# CY8C4245AXI_483 register map
File version: 0.1
PSoC 4200
Registers are 32-bit, read-write, no defined reset value unless marked. A register's access mark holds for its fields unless they carry their own. Offsets are from the block's base; lines under a group give offsets from that group; [hi:lo] are bit positions; {n}, {i} and the like mark numbered series; 'fields as' and 'values as' point back to an identical list; <NAME> marks a mode.

## Memory map
0x00000000 Timer_1
0x00000000 ADC — Sequencing SAR ADC
0x00000000 IDAC

## Timer_1
Base 0x00000000
0x400F0002 Timer_1_COUNTER 16-bit — UDB.A0 - Current Down Counter Value
0x400F0022 Timer_1_PERIOD 16-bit — UDB.D0 - Assigned Period
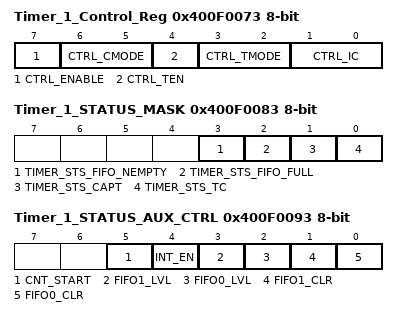
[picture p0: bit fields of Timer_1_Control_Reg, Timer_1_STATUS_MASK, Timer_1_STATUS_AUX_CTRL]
0x400F0073 Timer_1_Control_Reg 8-bit — UDB Control Register - Assigned Control Register Value
  [7] CTRL_ENABLE — Enable the Timer
  [6:5] CTRL_CMODE — Capture Mode
  [4] CTRL_TEN — Trigger Enable Bit
  [3:2] CTRL_TMODE — Trigger Mode
  [1:0] CTRL_IC — Interrupt Count
0x400F0083 Timer_1_STATUS_MASK 8-bit — UDB Status bits Interrupt Mask Enable Register
  [3] TIMER_STS_FIFO_NEMPTY ro — FIFO Empty status
  [2] TIMER_STS_FIFO_FULL ro — FIFO Full Status
  [1] TIMER_STS_CAPT ro — Enables the Interrupt on Capture
  [0] TIMER_STS_TC ro — Enables the Interrupt on TC
0x400F0093 Timer_1_STATUS_AUX_CTRL 8-bit — UDB Auxilliary Control Register
  [5] CNT_START — FIFO0 clear
    0=E_CNT_START0 (Disable counter); 1=E_CNT_START1 (Enable counter)
  [4] INT_EN
    0=E_INT_EN0 (Interrupt disabled); 1=E_INT_EN1 (Interrupt enabled)
  [3] FIFO1_LVL — FIFO level
    0=E_FIFO_LVL_0 (FIFO LVL: input mode: FIFO not full; output mode: FIFO not empty); 1=E_FIFO_LVL_1 (FIFO LVL: input mode: FIFO at least 1/2 empty; output mode: FIFO at least 1/2 full)
  [2] FIFO0_LVL — FIFO level
    values as FIFO1_LVL
  [1] FIFO1_CLR — FIFO1 clear
    0=E_FIFO_CLR_0 (Normal FIFO operation); 1=E_FIFO_CLR_1 (Clear FIFO state)
  [0] FIFO0_CLR — FIFO0 clear
    values as FIFO1_CLR

## IDAC
Base 0x00000000
0x40080004 CSD_IDAC_POLARITY
0x40080008 CSD_IDAC
0x4008FF00 CSD_TRIM1 — CSD IDAC TRIM1
0x4008FF04 CSD_TRIM2 — CSD IDAC TRIM2
